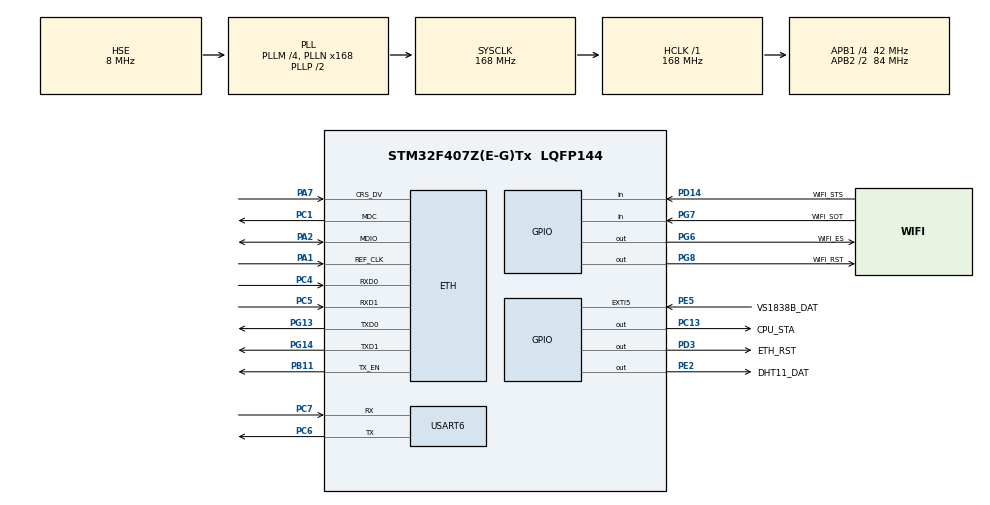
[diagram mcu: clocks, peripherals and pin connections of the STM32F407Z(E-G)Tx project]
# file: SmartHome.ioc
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Dma.Request0=USART6_RX
Dma.Request1=USART6_TX
Dma.USART6_RX.0.Direction=DMA_PERIPH_TO_MEMORY
Dma.USART6_RX.0.FIFOMode=DMA_FIFOMODE_DISABLE
Dma.USART6_RX.0.Instance=DMA2_Stream1
Dma.USART6_RX.0.MemDataAlignment=DMA_MDATAALIGN_BYTE
Dma.USART6_RX.0.MemInc=DMA_MINC_ENABLE
Dma.USART6_RX.0.Mode=DMA_NORMAL
Dma.USART6_RX.0.PeriphDataAlignment=DMA_PDATAALIGN_BYTE
Dma.USART6_RX.0.PeriphInc=DMA_PINC_DISABLE
Dma.USART6_RX.0.Priority=DMA_PRIORITY_LOW
Dma.USART6_TX.1.Direction=DMA_MEMORY_TO_PERIPH
Dma.USART6_TX.1.FIFOMode=DMA_FIFOMODE_DISABLE
Dma.USART6_TX.1.Instance=DMA2_Stream6
Dma.USART6_TX.1.MemDataAlignment=DMA_MDATAALIGN_BYTE
Dma.USART6_TX.1.MemInc=DMA_MINC_ENABLE
Dma.USART6_TX.1.Mode=DMA_NORMAL
Dma.USART6_TX.1.PeriphDataAlignment=DMA_PDATAALIGN_BYTE
Dma.USART6_TX.1.PeriphInc=DMA_PINC_DISABLE
Dma.USART6_TX.1.Priority=DMA_PRIORITY_LOW
ETH.MediaInterface=HAL_ETH_RMII_MODE
FREERTOS.Tasks01=defaultTask,24,256,StartDefaultTask,Default,NULL,Dynamic,NULL,NULL
FREERTOS.configTOTAL_HEAP_SIZE=30720
LWIP.BSP.number=1
LWIP.GATEWAY_ADDRESS=192.168.031.001
LWIP.IP_ADDRESS=192.168.031.200
LWIP.LWIP_DHCP=0
LWIP.NETMASK_ADDRESS=255.255.255.000
LWIP.Version=v2.1.2_Cube
LWIP0.BSP.STBoard=false
LWIP0.BSP.api=BSP_COMPONENT_DRIVER
LWIP0.BSP.component=LAN8742
LWIP0.BSP.instance=LAN8742
LWIP0.BSP.name=Driver_PHY
LWIP0.BSP.semaphore=S_LAN8742
LWIP0.BSP.solution=LAN8742
Mcu.Family=STM32F4
Mcu.Name=STM32F407Z(E-G)Tx
Mcu.Package=LQFP144
NVIC.DMA2_Stream1_IRQn=true\:5\:0\:false\:false\:true\:true\:false\:true\:true
NVIC.DMA2_Stream6_IRQn=true\:5\:0\:false\:false\:true\:true\:false\:true\:true
NVIC.ETH_IRQn=true\:5\:0\:false\:false\:true\:true\:false\:true\:true
NVIC.EXTI9_5_IRQn=true\:5\:0\:false\:false\:true\:true\:true\:true\:true
NVIC.PriorityGroup=NVIC_PRIORITYGROUP_4
NVIC.TIM6_DAC_IRQn=true\:5\:0\:false\:false\:true\:true\:true\:true\:true
NVIC.TIM8_TRG_COM_TIM14_IRQn=true\:15\:0\:false\:false\:true\:false\:false\:true\:true
NVIC.TimeBase=TIM8_TRG_COM_TIM14_IRQn
NVIC.TimeBaseIP=TIM14
NVIC.USART6_IRQn=true\:5\:0\:false\:false\:true\:true\:true\:true\:true
PA1.Mode=RMII
PA1.Signal=ETH_REF_CLK
PA13.Mode=Serial_Wire
PA13.Signal=SYS_JTMS-SWDIO
PA14.Mode=Serial_Wire
PA14.Signal=SYS_JTCK-SWCLK
PA2.Mode=RMII
PA2.Signal=ETH_MDIO
PA7.Mode=RMII
PA7.Signal=ETH_CRS_DV
PB11.Mode=RMII
PB11.Signal=ETH_TX_EN
PC1.Mode=RMII
PC1.Signal=ETH_MDC
PC13-ANTI_TAMP.GPIO_Label=CPU_STA
PC13-ANTI_TAMP.Signal=GPIO_Output
PC4.Mode=RMII
PC4.Signal=ETH_RXD0
PC5.Mode=RMII
PC5.Signal=ETH_RXD1
PC6.Mode=Asynchronous
PC6.Signal=USART6_TX
PC7.Mode=Asynchronous
PC7.Signal=USART6_RX
PD14.GPIO_Label=WIFI_STS
PD14.Signal=GPIO_Input
PD3.GPIO_Label=ETH_RST
PD3.Signal=GPIO_Output
PE2.GPIO_Label=DHT11_DAT
PE2.GPIO_PuPd=GPIO_PULLUP
PE2.GPIO_Speed=GPIO_SPEED_FREQ_HIGH
PE2.Signal=GPIO_Output
PE5.GPIO_Label=VS1838B_DAT
PE5.GPIO_ModeDefaultEXTI=GPIO_MODE_IT_RISING_FALLING
PE5.Signal=GPXTI5
PG13.Mode=RMII
PG13.Signal=ETH_TXD0
PG14.Mode=RMII
PG14.Signal=ETH_TXD1
PG6.GPIO_Label=WIFI_ES
PG6.Signal=GPIO_Output
PG7.GPIO_Label=WIFI_SOT
PG7.Signal=GPIO_Input
PG8.GPIO_Label=WIFI_RST
PG8.Signal=GPIO_Output
PH0-OSC_IN.Mode=HSE-External-Oscillator
PH0-OSC_IN.Signal=RCC_OSC_IN
PH1-OSC_OUT.Mode=HSE-External-Oscillator
PH1-OSC_OUT.Signal=RCC_OSC_OUT
ProjectManager.HeapSize=0x200
ProjectManager.StackSize=0x400
ProjectManager.TargetToolchain=CMake
RCC.48MHZClocksFreq_Value=84000000
RCC.AHBFreq_Value=168000000
RCC.APB1CLKDivider=RCC_HCLK_DIV4
RCC.APB1Freq_Value=42000000
RCC.APB1TimFreq_Value=84000000
RCC.APB2CLKDivider=RCC_HCLK_DIV2
RCC.APB2Freq_Value=84000000
RCC.APB2TimFreq_Value=168000000
RCC.CortexFreq_Value=168000000
RCC.HCLKFreq_Value=168000000
RCC.HSE_VALUE=8000000
RCC.HSI_VALUE=16000000
RCC.LSE_VALUE=32768
RCC.PLLM=4
RCC.PLLN=168
RCC.PLLSourceVirtual=RCC_PLLSOURCE_HSE
RCC.SYSCLKFreq_VALUE=168000000
RCC.SYSCLKSource=RCC_SYSCLKSOURCE_PLLCLK
RCC.VCOOutputFreq_Value=336000000
TIM6.AutoReloadPreload=TIM_AUTORELOAD_PRELOAD_ENABLE
TIM6.Period=1000-1
TIM6.Prescaler=84-1
USART6.VirtualMode=VM_ASYNC
VP_FREERTOS_VS_CMSIS_V2.Mode=CMSIS_V2
VP_LWIP_VS_Enabled.Mode=Enabled
VP_SYS_VS_tim14.Mode=TIM14
VP_TIM6_VS_ClockSourceINT.Mode=Enable_Timer
board=custom

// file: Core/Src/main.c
/* USER CODE BEGIN Header */
/**
  ******************************************************************************
  * @file           : main.c
  * @brief          : Main program body
  ******************************************************************************
  * @attention
  *
  * Copyright (c) 2026 STMicroelectronics.
  * All rights reserved.
  *
  * This software is licensed under terms that can be found in the LICENSE file
  * in the root directory of this software component.
  * If no LICENSE file comes with this software, it is provided AS-IS.
  *
  ******************************************************************************
  */
/* USER CODE END Header */
#include "main.h"
#include "cmsis_os.h"
#include "dma.h"
#include "lwip.h"
#include "tim.h"
#include "usart.h"
#include "gpio.h"

/* USER CODE BEGIN Includes */
#include "ir_receiver.h"
/* USER CODE END Includes */

void SystemClock_Config(void);
void MX_FREERTOS_Init(void);

int main(void)
{

  /* MCU Configuration--------------------------------------------------------*/

  /* Reset of all peripherals, Initializes the Flash interface and the Systick. */
  HAL_Init();

  /* Configure the system clock */
  SystemClock_Config();

  /* Initialize all configured peripherals */
  MX_GPIO_Init();
  MX_DMA_Init();
  MX_USART6_UART_Init();
  MX_TIM6_Init();

  /* Init scheduler */
  osKernelInitialize();  /* Call init function for freertos objects (in cmsis_os2.c) */
  MX_FREERTOS_Init();

  /* Start scheduler */
  osKernelStart();

  /* We should never get here as control is now taken by the scheduler */

  /* Infinite loop */
  while (1)
  {

  }
}

void SystemClock_Config(void)
{
  RCC_OscInitTypeDef RCC_OscInitStruct = {0};
  RCC_ClkInitTypeDef RCC_ClkInitStruct = {0};

  /** Configure the main internal regulator output voltage
  */
  __HAL_RCC_PWR_CLK_ENABLE();
  __HAL_PWR_VOLTAGESCALING_CONFIG(PWR_REGULATOR_VOLTAGE_SCALE1);

  /** Initializes the RCC Oscillators according to the specified parameters
  * in the RCC_OscInitTypeDef structure.
  */
  RCC_OscInitStruct.OscillatorType = RCC_OSCILLATORTYPE_HSE;
  RCC_OscInitStruct.HSEState = RCC_HSE_ON;
  RCC_OscInitStruct.PLL.PLLState = RCC_PLL_ON;
  RCC_OscInitStruct.PLL.PLLSource = RCC_PLLSOURCE_HSE;
  RCC_OscInitStruct.PLL.PLLM = 4;
  RCC_OscInitStruct.PLL.PLLN = 168;
  RCC_OscInitStruct.PLL.PLLP = RCC_PLLP_DIV2;
  RCC_OscInitStruct.PLL.PLLQ = 4;
  if (HAL_RCC_OscConfig(&RCC_OscInitStruct) != HAL_OK)
  {
    Error_Handler();
  }

  /** Initializes the CPU, AHB and APB buses clocks
  */
  RCC_ClkInitStruct.ClockType = RCC_CLOCKTYPE_HCLK|RCC_CLOCKTYPE_SYSCLK
                              |RCC_CLOCKTYPE_PCLK1|RCC_CLOCKTYPE_PCLK2;
  RCC_ClkInitStruct.SYSCLKSource = RCC_SYSCLKSOURCE_PLLCLK;
  RCC_ClkInitStruct.AHBCLKDivider = RCC_SYSCLK_DIV1;
  RCC_ClkInitStruct.APB1CLKDivider = RCC_HCLK_DIV4;
  RCC_ClkInitStruct.APB2CLKDivider = RCC_HCLK_DIV2;

  if (HAL_RCC_ClockConfig(&RCC_ClkInitStruct, FLASH_LATENCY_5) != HAL_OK)
  {
    Error_Handler();
  }
}

void HAL_TIM_PeriodElapsedCallback(TIM_HandleTypeDef *htim)
{
  if (htim->Instance == TIM14)
  {
    HAL_IncTick();
  }
}

void Error_Handler(void)
{
  __disable_irq();
  while (1)
  {
  }
}

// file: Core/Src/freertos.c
/* USER CODE BEGIN Header */
/**
  ******************************************************************************
  * File Name          : freertos.c
  * Description        : Code for freertos applications
  ******************************************************************************
  * @attention
  *
  * Copyright (c) 2026 STMicroelectronics.
  * All rights reserved.
  *
  * This software is licensed under terms that can be found in the LICENSE file
  * in the root directory of this software component.
  * If no LICENSE file comes with this software, it is provided AS-IS.
  *
  ******************************************************************************
  */
/* USER CODE END Header */

#include "FreeRTOS.h"
#include "task.h"
#include "main.h"
#include "cmsis_os.h"

/* USER CODE BEGIN Includes */
#include "app_main.h"
/* USER CODE END Includes */

/* Definitions for defaultTask */
osThreadId_t defaultTaskHandle;
const osThreadAttr_t defaultTask_attributes = {
  .name = "defaultTask",
  .stack_size = 256 * 4,
  .priority = (osPriority_t) osPriorityNormal,
};

void StartDefaultTask(void *argument);

extern void MX_LWIP_Init(void);
void MX_FREERTOS_Init(void); /* (MISRA C 2004 rule 8.1) */

void MX_FREERTOS_Init(void) {
  /* USER CODE BEGIN Init */
  app_main_init();
  /* USER CODE END Init */

  /* Create the thread(s) */
  /* creation of defaultTask */
  defaultTaskHandle = osThreadNew(StartDefaultTask, NULL, &defaultTask_attributes);

}

void StartDefaultTask(void *argument)
{
  /* init code for LWIP */
  MX_LWIP_Init();
  /* USER CODE BEGIN StartDefaultTask */
  app_main_task();
  /* Infinite loop */
  for(;;)
  {
    osDelay(500);
  }
  /* USER CODE END StartDefaultTask */
}
